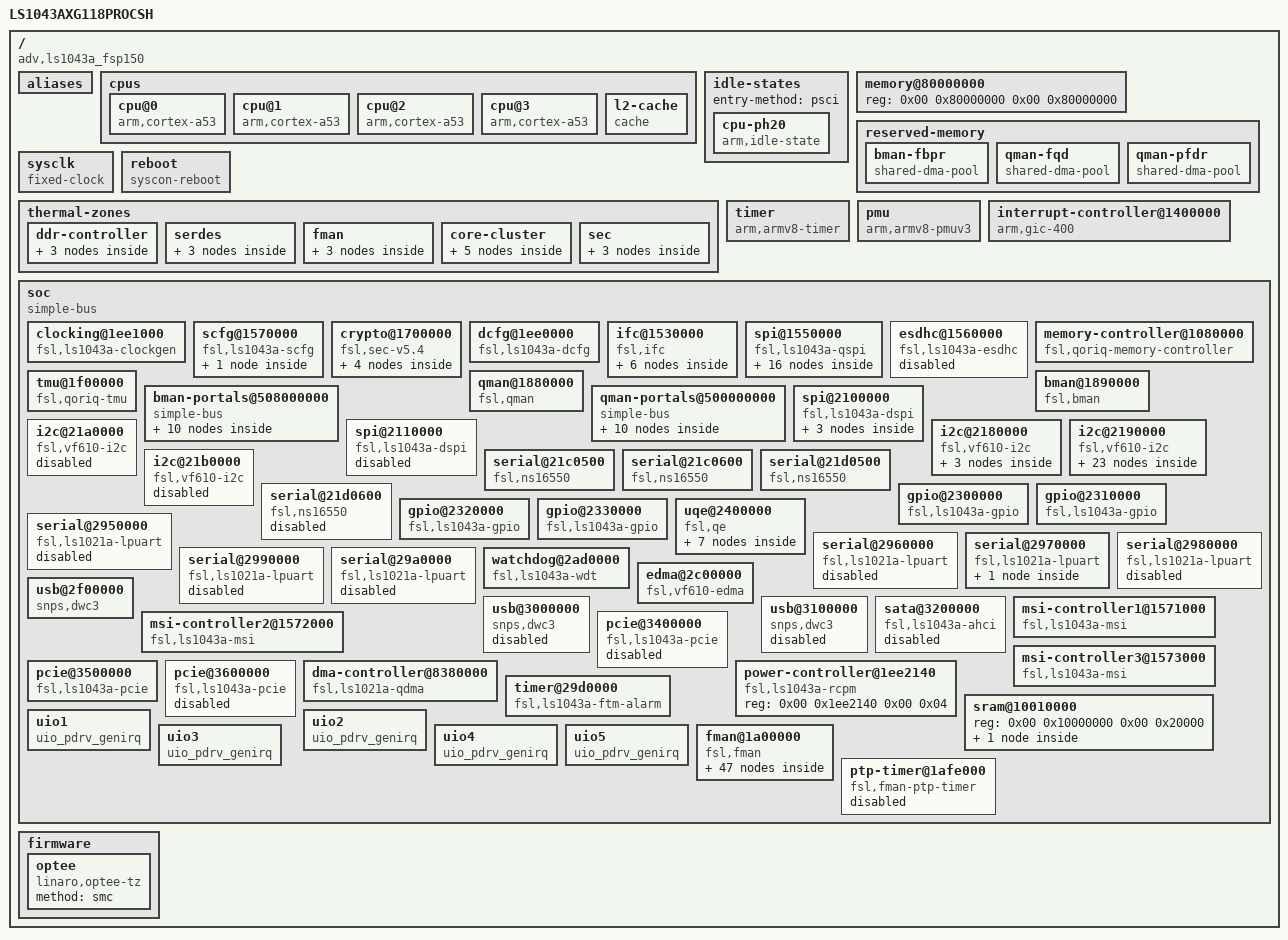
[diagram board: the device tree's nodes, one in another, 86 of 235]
/dts-v1/;

/ {
	revision = "#REV#";
	model = "LS1043AXG118PROCSH";
	compatible = "adv,ls1043a_fsp150\0fsl,ls1043a";
	interrupt-parent = <0x01>;
	#address-cells = <0x02>;
	#size-cells = <0x02>;
	fpga_bus = "pcie";

	aliases {
		crypto = "/soc/crypto@1700000";
		fman0 = "/soc/fman@1a00000";
		ethernet0 = "/soc/fman@1a00000/ethernet@e2000";
		ethernet1 = "/soc/fman@1a00000/ethernet@e4000";
		ethernet2 = "/soc/fman@1a00000/ethernet@f0000";
		rtc1 = "/soc/timer@29d0000";
		serial0 = "/soc/serial@21c0500";
		serial1 = "/soc/serial@21c0600";
		serial2 = "/soc/serial@21d0500";
		lpserial0 = "/soc/serial@2970000";
	};

	cpus {
		#address-cells = <0x01>;
		#size-cells = <0x00>;

		cpu@0 {
			device_type = "cpu";
			compatible = "arm,cortex-a53";
			reg = <0x00>;
			clocks = <0x02 0x01 0x00>;
			next-level-cache = <0x03>;
			cpu-idle-states = <0x04>;
			#cooling-cells = <0x02>;
			phandle = <0x08>;
		};

		cpu@1 {
			device_type = "cpu";
			compatible = "arm,cortex-a53";
			reg = <0x01>;
			clocks = <0x02 0x01 0x00>;
			next-level-cache = <0x03>;
			cpu-idle-states = <0x04>;
			#cooling-cells = <0x02>;
			phandle = <0x09>;
		};

		cpu@2 {
			device_type = "cpu";
			compatible = "arm,cortex-a53";
			reg = <0x02>;
			clocks = <0x02 0x01 0x00>;
			next-level-cache = <0x03>;
			cpu-idle-states = <0x04>;
			#cooling-cells = <0x02>;
			phandle = <0x0a>;
		};

		cpu@3 {
			device_type = "cpu";
			compatible = "arm,cortex-a53";
			reg = <0x03>;
			clocks = <0x02 0x01 0x00>;
			next-level-cache = <0x03>;
			cpu-idle-states = <0x04>;
			#cooling-cells = <0x02>;
			phandle = <0x0b>;
		};

		l2-cache {
			compatible = "cache";
			phandle = <0x03>;
		};
	};

	idle-states {
		entry-method = "psci";

		cpu-ph20 {
			compatible = "arm,idle-state";
			idle-state-name = "PH20";
			arm,psci-suspend-param = <0x00>;
			entry-latency-us = <0x3e8>;
			exit-latency-us = <0x3e8>;
			min-residency-us = <0xbb8>;
			phandle = <0x04>;
		};
	};

	memory@80000000 {
		device_type = "memory";
		reg = <0x00 0x80000000 0x00 0x80000000>;
	};

	reserved-memory {
		#address-cells = <0x02>;
		#size-cells = <0x02>;
		ranges;

		bman-fbpr {
			compatible = "shared-dma-pool";
			size = <0x00 0x1000000>;
			alignment = <0x00 0x1000000>;
			no-map;
			phandle = <0x0f>;
		};

		qman-fqd {
			compatible = "shared-dma-pool";
			size = <0x00 0x400000>;
			alignment = <0x00 0x400000>;
			no-map;
			phandle = <0x0d>;
		};

		qman-pfdr {
			compatible = "shared-dma-pool";
			size = <0x00 0x2000000>;
			alignment = <0x00 0x2000000>;
			no-map;
			phandle = <0x0e>;
		};
	};

	sysclk {
		compatible = "fixed-clock";
		#clock-cells = <0x00>;
		clock-frequency = <0x5f5e100>;
		clock-output-names = "sysclk";
		phandle = <0x0c>;
	};

	reboot {
		compatible = "syscon-reboot";
		regmap = <0x05>;
		offset = <0xb0>;
		mask = <0x02>;
	};

	thermal-zones {

		ddr-controller {
			polling-delay-passive = <0x3e8>;
			polling-delay = <0x1388>;
			thermal-sensors = <0x06 0x00>;

			trips {

				ddr-ctrler-alert {
					temperature = <0x14c08>;
					hysteresis = <0x7d0>;
					type = "passive";
				};

				ddr-ctrler-crit {
					temperature = <0x17318>;
					hysteresis = <0x7d0>;
					type = "critical";
				};
			};
		};

		serdes {
			polling-delay-passive = <0x3e8>;
			polling-delay = <0x1388>;
			thermal-sensors = <0x06 0x01>;

			trips {

				serdes-alert {
					temperature = <0x14c08>;
					hysteresis = <0x7d0>;
					type = "passive";
				};

				serdes-crit {
					temperature = <0x17318>;
					hysteresis = <0x7d0>;
					type = "critical";
				};
			};
		};

		fman {
			polling-delay-passive = <0x3e8>;
			polling-delay = <0x1388>;
			thermal-sensors = <0x06 0x02>;

			trips {

				fman-alert {
					temperature = <0x14c08>;
					hysteresis = <0x7d0>;
					type = "passive";
				};

				fman-crit {
					temperature = <0x17318>;
					hysteresis = <0x7d0>;
					type = "critical";
				};
			};
		};

		core-cluster {
			polling-delay-passive = <0x3e8>;
			polling-delay = <0x1388>;
			thermal-sensors = <0x06 0x03>;

			trips {

				core-cluster-alert {
					temperature = <0x14c08>;
					hysteresis = <0x7d0>;
					type = "passive";
					phandle = <0x07>;
				};

				core-cluster-crit {
					temperature = <0x17318>;
					hysteresis = <0x7d0>;
					type = "critical";
				};
			};

			cooling-maps {

				map0 {
					trip = <0x07>;
					cooling-device = <0x08 0xffffffff 0xffffffff 0x09 0xffffffff 0xffffffff 0x0a 0xffffffff 0xffffffff 0x0b 0xffffffff 0xffffffff>;
				};
			};
		};

		sec {
			polling-delay-passive = <0x3e8>;
			polling-delay = <0x1388>;
			thermal-sensors = <0x06 0x04>;

			trips {

				sec-alert {
					temperature = <0x14c08>;
					hysteresis = <0x7d0>;
					type = "passive";
				};

				sec-crit {
					temperature = <0x17318>;
					hysteresis = <0x7d0>;
					type = "critical";
				};
			};
		};
	};

	timer {
		compatible = "arm,armv8-timer";
		interrupts = <0x01 0x0d 0xf08 0x01 0x0e 0xf08 0x01 0x0b 0xf08 0x01 0x0a 0xf08>;
		fsl,erratum-a008585;
	};

	pmu {
		compatible = "arm,armv8-pmuv3";
		interrupts = <0x00 0x6a 0x04 0x00 0x6b 0x04 0x00 0x5f 0x04 0x00 0x61 0x04>;
		interrupt-affinity = <0x08 0x09 0x0a 0x0b>;
	};

	interrupt-controller@1400000 {
		compatible = "arm,gic-400";
		#interrupt-cells = <0x03>;
		interrupt-controller;
		reg = <0x00 0x1401000 0x00 0x1000 0x00 0x1402000 0x00 0x2000 0x00 0x1404000 0x00 0x2000 0x00 0x1406000 0x00 0x2000>;
		interrupts = <0x01 0x09 0xf08>;
		phandle = <0x01>;
	};

	soc {
		compatible = "simple-bus";
		#address-cells = <0x02>;
		#size-cells = <0x02>;
		ranges;

		clocking@1ee1000 {
			compatible = "fsl,ls1043a-clockgen";
			reg = <0x00 0x1ee1000 0x00 0x1000>;
			#clock-cells = <0x02>;
			clocks = <0x0c>;
			phandle = <0x02>;
		};

		scfg@1570000 {
			compatible = "fsl,ls1043a-scfg\0syscon";
			reg = <0x00 0x1570000 0x00 0x10000>;
			big-endian;
			#address-cells = <0x01>;
			#size-cells = <0x01>;
			ranges = <0x00 0x00 0x1570000 0x10000>;

			interrupt-controller@1ac {
				compatible = "fsl,ls1043a-extirq";
				#interrupt-cells = <0x02>;
				#address-cells = <0x00>;
				interrupt-controller;
				reg = <0x1ac 0x04>;
				interrupt-map = <0x00 0x00 0x01 0x00 0x83 0x04 0x01 0x00 0x01 0x00 0x84 0x04 0x02 0x00 0x01 0x00 0x85 0x04 0x03 0x00 0x01 0x00 0x87 0x04 0x04 0x00 0x01 0x00 0x88 0x04 0x05 0x00 0x01 0x00 0x89 0x04 0x06 0x00 0x01 0x00 0x91 0x04 0x07 0x00 0x01 0x00 0x92 0x04 0x08 0x00 0x01 0x00 0x93 0x04 0x09 0x00 0x01 0x00 0x95 0x04 0x0a 0x00 0x01 0x00 0x96 0x04 0x0b 0x00 0x01 0x00 0x97 0x04>;
				interrupt-map-mask = <0xffffffff 0x00>;
			};
		};

		crypto@1700000 {
			compatible = "fsl,sec-v5.4\0fsl,sec-v5.0\0fsl,sec-v4.0";
			fsl,sec-era = <0x03>;
			#address-cells = <0x01>;
			#size-cells = <0x01>;
			ranges = <0x00 0x00 0x1700000 0x100000>;
			reg = <0x00 0x1700000 0x00 0x100000>;
			interrupts = <0x00 0x4b 0x04>;
			dma-coherent;

			jr@10000 {
				compatible = "fsl,sec-v5.4-job-ring\0fsl,sec-v5.0-job-ring\0fsl,sec-v4.0-job-ring";
				reg = <0x10000 0x10000>;
				interrupts = <0x00 0x47 0x04>;
			};

			jr@20000 {
				compatible = "fsl,sec-v5.4-job-ring\0fsl,sec-v5.0-job-ring\0fsl,sec-v4.0-job-ring";
				reg = <0x20000 0x10000>;
				interrupts = <0x00 0x48 0x04>;
			};

			jr@30000 {
				compatible = "fsl,sec-v5.4-job-ring\0fsl,sec-v5.0-job-ring\0fsl,sec-v4.0-job-ring";
				reg = <0x30000 0x10000>;
				interrupts = <0x00 0x49 0x04>;
			};

			jr@40000 {
				compatible = "fsl,sec-v5.4-job-ring\0fsl,sec-v5.0-job-ring\0fsl,sec-v4.0-job-ring";
				reg = <0x40000 0x10000>;
				interrupts = <0x00 0x4a 0x04>;
			};
		};

		dcfg@1ee0000 {
			compatible = "fsl,ls1043a-dcfg\0syscon";
			reg = <0x00 0x1ee0000 0x00 0x10000>;
			big-endian;
			phandle = <0x05>;
		};

		ifc@1530000 {
			compatible = "fsl,ifc\0simple-bus";
			reg = <0x00 0x1530000 0x00 0x10000>;
			interrupts = <0x00 0x2b 0x04>;
			#address-cells = <0x02>;
			#size-cells = <0x01>;
			status = "okay";
			ranges = <0x00 0x00 0x00 0x68000000 0x10000 0x02 0x00 0x00 0x78000000 0x1000>;

			nand@0,0 {
				compatible = "fsl,ifc-nand";
				#address-cells = <0x02>;
				#size-cells = <0x02>;
				reg = <0x00 0x00 0x10000>;
				num-cs = <0x02>;

				partition@0 {
					label = "ubi";
					reg = <0x00 0x00 0x02 0x00>;
				};
			};

			cpld@2,0 {
				compatible = "fsl,ls1043ardb-cpld\0adv,fsp150-cpld\0uio_pdrv_genirq";
				#address-cells = <0x01>;
				#size-cells = <0x01>;
				reg = <0x02 0x00 0x1000>;
				device-width = <0x02>;
				ranges = <0x00 0x02 0x00 0x200>;
				interrupt-parent = <0x01>;

				hwversion@2 {
					reg = <0x02 0x02>;
				};

				restartcause@fe {
					reg = <0xfe 0x02>;
				};

				watchdog@f6 {
					reg = <0xf6 0x08>;
				};
			};
		};

		spi@1550000 {
			compatible = "fsl,ls1043a-qspi\0fsl,ls1021a-qspi";
			#address-cells = <0x01>;
			#size-cells = <0x00>;
			reg = <0x00 0x1550000 0x00 0x10000 0x00 0x40000000 0x00 0x4000000>;
			reg-names = "QuadSPI\0QuadSPI-memory";
			interrupts = <0x00 0x63 0x04>;
			clock-names = "qspi_en\0qspi";
			clocks = <0x02 0x04 0x00 0x02 0x04 0x00>;
			status = "okay";
			spi-max-frequency = <0x2faf080>;
			fsl,qspi-has-second-chip;

			mx25r1635f@0 {
				compatible = "micronix,mx25r1635f\0jedec,spi-nor";
				#address-cells = <0x01>;
				#size-cells = <0x01>;
				spi-max-frequency = <0x2faf080>;
				reg = <0x00>;

				partition@0 {
					reg = <0x00 0x10000>;
					label = "rcw";
				};

				partition@10000 {
					reg = <0x10000 0xde000>;
					label = "csf";
				};

				partition@ee000 {
					reg = <0xee000 0x1000>;
					label = "env1";
				};

				partition@ef000 {
					reg = <0xef000 0x1000>;
					label = "env2";
				};

				partition@f0000 {
					reg = <0xf0000 0x10000>;
					label = "pbuf";
				};

				partition@100000 {
					reg = <0x100000 0x100000>;
					label = "unused";
				};

				nor@200000 {
					reg = <0x00 0x200000>;
					label = "nor";
				};
			};

			mx25r1635f@1 {
				compatible = "micronix,mx25r1635f\0jedec,spi-nor";
				#address-cells = <0x01>;
				#size-cells = <0x01>;
				spi-max-frequency = <0x2faf080>;
				reg = <0x01>;

				partition@0 {
					reg = <0x00 0x10000>;
					label = "rcw_standby";
				};

				partition@10000 {
					reg = <0x10000 0xde000>;
					label = "csf_standby";
				};

				partition@ee000 {
					reg = <0xee000 0x1000>;
					label = "env1_standby";
				};

				partition@ef000 {
					reg = <0xef000 0x1000>;
					label = "env2_standby";
				};

				partition@f0000 {
					reg = <0xf0000 0x10000>;
					label = "pbuf_standby";
				};

				partition@100000 {
					reg = <0x100000 0x100000>;
					label = "unused_standby";
				};

				nor@200000 {
					reg = <0x00 0x200000>;
					label = "nor_standby";
				};
			};
		};

		esdhc@1560000 {
			compatible = "fsl,ls1043a-esdhc\0fsl,esdhc";
			reg = <0x00 0x1560000 0x00 0x10000>;
			interrupts = <0x00 0x3e 0x04>;
			clock-frequency = <0x00>;
			voltage-ranges = <0x708 0x708 0xce4 0xce4>;
			sdhci,auto-cmd12;
			big-endian;
			bus-width = <0x04>;
			status = "disabled";
		};

		memory-controller@1080000 {
			compatible = "fsl,qoriq-memory-controller";
			reg = <0x00 0x1080000 0x00 0x1000>;
			interrupts = <0x00 0x90 0x04>;
			big-endian;
		};

		tmu@1f00000 {
			compatible = "fsl,qoriq-tmu";
			reg = <0x00 0x1f00000 0x00 0x10000>;
			interrupts = <0x00 0x21 0x04>;
			fsl,tmu-range = <0xb0000 0x9002a 0x6004c 0x70062>;
			fsl,tmu-calibration = <0x00 0x23 0x01 0x2a 0x02 0x31 0x03 0x37 0x04 0x3e 0x05 0x44 0x06 0x4b 0x07 0x51 0x08 0x58 0x09 0x5e 0x0a 0x65 0x0b 0x6b 0x10000 0x23 0x10001 0x2b 0x10002 0x33 0x10003 0x3b 0x10004 0x43 0x10005 0x4b 0x10006 0x54 0x10007 0x5c 0x10008 0x64 0x10009 0x6c 0x20000 0x21 0x20001 0x2c 0x20002 0x36 0x20003 0x40 0x20004 0x4b 0x20005 0x55 0x20006 0x5f 0x30000 0x13 0x30001 0x1d 0x30002 0x28 0x30003 0x32 0x30004 0x3d 0x30005 0x47 0x30006 0x52 0x30007 0x5c>;
			#thermal-sensor-cells = <0x01>;
			phandle = <0x06>;
		};

		qman@1880000 {
			compatible = "fsl,qman";
			reg = <0x00 0x1880000 0x00 0x10000>;
			interrupts = <0x00 0x2d 0x04>;
			memory-region = <0x0d 0x0e>;
		};

		bman@1890000 {
			compatible = "fsl,bman";
			reg = <0x00 0x1890000 0x00 0x10000>;
			interrupts = <0x00 0x2d 0x04>;
			memory-region = <0x0f>;
		};

		bman-portals@508000000 {
			ranges = <0x00 0x05 0x8000000 0x8000000>;
			#address-cells = <0x01>;
			#size-cells = <0x01>;
			compatible = "simple-bus";

			bman-portal@0 {
				compatible = "fsl,bman-portal";
				reg = <0x00 0x4000 0x4000000 0x4000>;
				interrupts = <0x00 0xad 0x04>;
			};

			bman-portal@10000 {
				compatible = "fsl,bman-portal";
				reg = <0x10000 0x4000 0x4010000 0x4000>;
				interrupts = <0x00 0xaf 0x04>;
			};

			bman-portal@20000 {
				compatible = "fsl,bman-portal";
				reg = <0x20000 0x4000 0x4020000 0x4000>;
				interrupts = <0x00 0xb1 0x04>;
			};

			bman-portal@30000 {
				compatible = "fsl,bman-portal";
				reg = <0x30000 0x4000 0x4030000 0x4000>;
				interrupts = <0x00 0xb3 0x04>;
			};

			bman-portal@40000 {
				compatible = "fsl,bman-portal";
				reg = <0x40000 0x4000 0x4040000 0x4000>;
				interrupts = <0x00 0xb5 0x04>;
			};

			bman-portal@50000 {
				compatible = "fsl,bman-portal";
				reg = <0x50000 0x4000 0x4050000 0x4000>;
				interrupts = <0x00 0xb7 0x04>;
			};

			bman-portal@60000 {
				compatible = "fsl,bman-portal";
				reg = <0x60000 0x4000 0x4060000 0x4000>;
				interrupts = <0x00 0xb9 0x04>;
			};

			bman-portal@70000 {
				compatible = "fsl,bman-portal";
				reg = <0x70000 0x4000 0x4070000 0x4000>;
				interrupts = <0x00 0xbb 0x04>;
			};

			bman-portal@80000 {
				compatible = "fsl,bman-portal";
				reg = <0x80000 0x4000 0x4080000 0x4000>;
				interrupts = <0x00 0xbd 0x04>;
			};

			bman-portal@90000 {
				compatible = "fsl,bman-portal";
				reg = <0x90000 0x4000 0x4090000 0x4000>;
				interrupts = <0x00 0xbf 0x04>;
			};
		};

		qman-portals@500000000 {
			ranges = <0x00 0x05 0x00 0x8000000>;
			#address-cells = <0x01>;
			#size-cells = <0x01>;
			compatible = "simple-bus";

			qman-portal@0 {
				compatible = "fsl,qman-portal";
				reg = <0x00 0x4000 0x4000000 0x4000>;
				interrupts = <0x00 0xac 0x04>;
				cell-index = <0x00>;
			};

			qman-portal@10000 {
				compatible = "fsl,qman-portal";
				reg = <0x10000 0x4000 0x4010000 0x4000>;
				interrupts = <0x00 0xae 0x04>;
				cell-index = <0x01>;
			};

			qman-portal@20000 {
				compatible = "fsl,qman-portal";
				reg = <0x20000 0x4000 0x4020000 0x4000>;
				interrupts = <0x00 0xb0 0x04>;
				cell-index = <0x02>;
			};

			qman-portal@30000 {
				compatible = "fsl,qman-portal";
				reg = <0x30000 0x4000 0x4030000 0x4000>;
				interrupts = <0x00 0xb2 0x04>;
				cell-index = <0x03>;
			};

			qman-portal@40000 {
				compatible = "fsl,qman-portal";
				reg = <0x40000 0x4000 0x4040000 0x4000>;
				interrupts = <0x00 0xb4 0x04>;
				cell-index = <0x04>;
			};

			qman-portal@50000 {
				compatible = "fsl,qman-portal";
				reg = <0x50000 0x4000 0x4050000 0x4000>;
				interrupts = <0x00 0xb6 0x04>;
				cell-index = <0x05>;
			};

			qman-portal@60000 {
				compatible = "fsl,qman-portal";
				reg = <0x60000 0x4000 0x4060000 0x4000>;
				interrupts = <0x00 0xb8 0x04>;
				cell-index = <0x06>;
			};

			qman-portal@70000 {
				compatible = "fsl,qman-portal";
				reg = <0x70000 0x4000 0x4070000 0x4000>;
				interrupts = <0x00 0xba 0x04>;
				cell-index = <0x07>;
			};

			qman-portal@80000 {
				compatible = "fsl,qman-portal";
				reg = <0x80000 0x4000 0x4080000 0x4000>;
				interrupts = <0x00 0xbc 0x04>;
				cell-index = <0x08>;
			};

			qman-portal@90000 {
				compatible = "fsl,qman-portal";
				reg = <0x90000 0x4000 0x4090000 0x4000>;
				interrupts = <0x00 0xbe 0x04>;
				cell-index = <0x09>;
			};
		};

		spi@2100000 {
			compatible = "fsl,ls1043a-dspi\0fsl,ls1021a-v1.0-dspi";
			#address-cells = <0x01>;
			#size-cells = <0x00>;
			reg = <0x00 0x2100000 0x00 0x10000>;
			interrupts = <0x00 0x40 0x04>;
			clock-names = "dspi";
			clocks = <0x02 0x04 0x00>;
			spi-num-chipselects = <0x03>;
			big-endian;
			status = "okay";
			bus-num = <0x00>;

			cs0@0 {
				compatible = "adv,spidev";
				spi-max-frequency = <0xf4240>;
				fsl,spi-cs-sck-delay = <0x32>;
				fsl,spi-sck-cs-delay = <0x32>;
				mode = <0x00>;
				reg = <0x00>;
			};

			cs1@1 {
				compatible = "adv,spidev";
				spi-max-frequency = <0xf4240>;
				fsl,spi-cs-sck-delay = <0x32>;
				fsl,spi-sck-cs-delay = <0x32>;
				mode = <0x00>;
				reg = <0x01>;
			};

			cs2@2 {
				compatible = "adv,spidev";
				spi-max-frequency = <0xf4240>;
				fsl,spi-cs-sck-delay = <0x69>;
				fsl,spi-sck-cs-delay = <0x6e>;
				mode = <0x00>;
				reg = <0x02>;
			};
		};

		spi@2110000 {
			compatible = "fsl,ls1043a-dspi\0fsl,ls1021a-v1.0-dspi";
			#address-cells = <0x01>;
			#size-cells = <0x00>;
			reg = <0x00 0x2110000 0x00 0x10000>;
			interrupts = <0x00 0x41 0x04>;
			clock-names = "dspi";
			clocks = <0x02 0x04 0x00>;
			spi-num-chipselects = <0x05>;
			big-endian;
			status = "disabled";
		};

		i2c@2180000 {
			compatible = "fsl,vf610-i2c";
			#address-cells = <0x01>;
			#size-cells = <0x00>;
			reg = <0x00 0x2180000 0x00 0x10000>;
			interrupts = <0x00 0x38 0x04>;
			clock-names = "i2c";
			clocks = <0x02 0x04 0x00>;
			dmas = <0x10 0x01 0x26 0x10 0x01 0x27>;
			dma-names = "rx\0tx";
			status = "okay";
			gpios = <0x11 0x1c 0x02 0x11 0x1f 0x02>;

			mcp9808@18 {
				compatible = "maxim,mcp980x";
				reg = <0x18>;
			};

			at24c08@54 {
				compatible = "atmel,24c08";
				reg = <0x54>;
			};

			rtc@68 {
				compatible = "dallas,ds1340";
				reg = <0x68>;
			};
		};

		i2c@2190000 {
			compatible = "fsl,vf610-i2c";
			#address-cells = <0x01>;
			#size-cells = <0x00>;
			reg = <0x00 0x2190000 0x00 0x10000>;
			interrupts = <0x00 0x39 0x04>;
			clock-names = "i2c";
			clocks = <0x02 0x04 0x00>;
			status = "okay";
			gpios = <0x11 0x1b 0x02 0x11 0x1a 0x02>;

			mux1@71 {
				compatible = "nxp,pca9548";
				reg = <0x71>;
				#address-cells = <0x01>;
				#size-cells = <0x00>;
				i2c-mux-idle-disconnect;

				channel0@0 {
					#address-cells = <0x01>;
					#size-cells = <0x00>;
					reg = <0x00>;
				};

				channel1@1 {
					#address-cells = <0x01>;
					#size-cells = <0x00>;
					reg = <0x01>;
				};

				channel2@2 {
					#address-cells = <0x01>;
					#size-cells = <0x00>;
					reg = <0x02>;
				};

				channel3@3 {
					#address-cells = <0x01>;
					#size-cells = <0x00>;
					reg = <0x03>;
				};

				channel4@4 {
					#address-cells = <0x01>;
					#size-cells = <0x00>;
					reg = <0x04>;
				};

				channel5@5 {
					#address-cells = <0x01>;
					#size-cells = <0x00>;
					reg = <0x05>;
				};

				channel6@6 {
					#address-cells = <0x01>;
					#size-cells = <0x00>;
					reg = <0x06>;
				};

				channel7@7 {
					#address-cells = <0x01>;
					#size-cells = <0x00>;
					reg = <0x07>;
				};
			};

			mux2@72 {
				compatible = "nxp,pca9548";
				reg = <0x72>;
				#address-cells = <0x01>;
				#size-cells = <0x00>;
				i2c-mux-idle-disconnect;

				channel0@0 {
					#address-cells = <0x01>;
					#size-cells = <0x00>;
					reg = <0x00>;
				};

				channel1@1 {
					#address-cells = <0x01>;
					#size-cells = <0x00>;
					reg = <0x01>;
				};

				channel2@2 {
					#address-cells = <0x01>;
					#size-cells = <0x00>;
					reg = <0x02>;
				};

				channel3@3 {
					#address-cells = <0x01>;
					#size-cells = <0x00>;
					reg = <0x03>;
				};

				channel4@4 {
					#address-cells = <0x01>;
					#size-cells = <0x00>;
					reg = <0x04>;
				};

				channel5@5 {
					#address-cells = <0x01>;
					#size-cells = <0x00>;
					reg = <0x05>;
				};

				channel6@6 {
					#address-cells = <0x01>;
					#size-cells = <0x00>;
					reg = <0x06>;
				};

				channel7@7 {
					#address-cells = <0x01>;
					#size-cells = <0x00>;
					reg = <0x07>;
				};
			};

			mux3@70 {
				compatible = "nxp,pca9545";
				reg = <0x70>;
				#address-cells = <0x01>;
				#size-cells = <0x00>;
				i2c-mux-idle-disconnect;

				channel0@0 {
					#address-cells = <0x01>;
					#size-cells = <0x00>;
					reg = <0x00>;
				};

				channel1@1 {
					#address-cells = <0x01>;
					#size-cells = <0x00>;
					reg = <0x01>;
				};

				channel2@2 {
					#address-cells = <0x01>;
					#size-cells = <0x00>;
					reg = <0x02>;
				};

				channel3@3 {
					#address-cells = <0x01>;
					#size-cells = <0x00>;
					reg = <0x03>;
				};
			};
		};

		i2c@21a0000 {
			compatible = "fsl,vf610-i2c";
			#address-cells = <0x01>;
			#size-cells = <0x00>;
			reg = <0x00 0x21a0000 0x00 0x10000>;
			interrupts = <0x00 0x3a 0x04>;
			clock-names = "i2c";
			clocks = <0x02 0x04 0x00>;
			status = "disabled";
		};

		i2c@21b0000 {
			compatible = "fsl,vf610-i2c";
			#address-cells = <0x01>;
			#size-cells = <0x00>;
			reg = <0x00 0x21b0000 0x00 0x10000>;
			interrupts = <0x00 0x3b 0x04>;
			clock-names = "i2c";
			clocks = <0x02 0x04 0x00>;
			status = "disabled";
		};

		serial@21c0500 {
			compatible = "fsl,ns16550\0ns16550a";
			reg = <0x00 0x21c0500 0x00 0x100>;
			interrupts = <0x00 0x36 0x04>;
			clocks = <0x02 0x04 0x00>;
			status = "okay";
		};

		serial@21c0600 {
			compatible = "fsl,ns16550\0ns16550a";
			reg = <0x00 0x21c0600 0x00 0x100>;
			interrupts = <0x00 0x36 0x04>;
			clocks = <0x02 0x04 0x00>;
			status = "okay";
		};

		serial@21d0500 {
			compatible = "fsl,ns16550\0ns16550a";
			reg = <0x00 0x21d0500 0x00 0x100>;
			interrupts = <0x00 0x37 0x04>;
			clocks = <0x02 0x04 0x00>;
			status = "okay";
		};

		serial@21d0600 {
			compatible = "fsl,ns16550\0ns16550a";
			reg = <0x00 0x21d0600 0x00 0x100>;
			interrupts = <0x00 0x37 0x04>;
			clocks = <0x02 0x04 0x00>;
			status = "disabled";
		};

		gpio@2300000 {
			compatible = "fsl,ls1043a-gpio\0fsl,qoriq-gpio";
			reg = <0x00 0x2300000 0x00 0x10000>;
			interrupts = <0x00 0x42 0x04>;
			gpio-controller;
			#gpio-cells = <0x02>;
			interrupt-controller;
			#interrupt-cells = <0x02>;
			phandle = <0x11>;
		};

		gpio@2310000 {
			compatible = "fsl,ls1043a-gpio\0fsl,qoriq-gpio";
			reg = <0x00 0x2310000 0x00 0x10000>;
			interrupts = <0x00 0x43 0x04>;
			gpio-controller;
			#gpio-cells = <0x02>;
			interrupt-controller;
			#interrupt-cells = <0x02>;
		};

		gpio@2320000 {
			compatible = "fsl,ls1043a-gpio\0fsl,qoriq-gpio";
			reg = <0x00 0x2320000 0x00 0x10000>;
			interrupts = <0x00 0x44 0x04>;
			gpio-controller;
			#gpio-cells = <0x02>;
			interrupt-controller;
			#interrupt-cells = <0x02>;
		};

		gpio@2330000 {
			compatible = "fsl,ls1043a-gpio\0fsl,qoriq-gpio";
			reg = <0x00 0x2330000 0x00 0x10000>;
			interrupts = <0x00 0x86 0x04>;
			gpio-controller;
			#gpio-cells = <0x02>;
			interrupt-controller;
			#interrupt-cells = <0x02>;
		};

		uqe@2400000 {
			#address-cells = <0x01>;
			#size-cells = <0x01>;
			compatible = "fsl,qe\0simple-bus";
			ranges = <0x00 0x00 0x2400000 0x40000>;
			reg = <0x00 0x2400000 0x00 0x480>;
			brg-frequency = <0x5f5e100>;
			bus-frequency = <0xbebc200>;
			fsl,qe-num-riscs = <0x01>;
			fsl,qe-num-snums = <0x1c>;

			qeic@80 {
				compatible = "fsl,qe-ic";
				reg = <0x80 0x80>;
				#address-cells = <0x00>;
				interrupt-controller;
				#interrupt-cells = <0x01>;
				interrupts = <0x00 0x4d 0x04 0x00 0x4d 0x04>;
				phandle = <0x12>;
			};

			si@700 {
				#address-cells = <0x01>;
				#size-cells = <0x00>;
				compatible = "fsl,ls1043-qe-si\0fsl,t1040-qe-si";
				reg = <0x700 0x80>;
			};

			siram@1000 {
				#address-cells = <0x01>;
				#size-cells = <0x01>;
				compatible = "fsl,ls1043-qe-siram\0fsl,t1040-qe-siram";
				reg = <0x1000 0x800>;
			};

			ucc@2000 {
				cell-index = <0x01>;
				reg = <0x2000 0x200>;
				interrupts = <0x20>;
				interrupt-parent = <0x12>;
			};

			ucc@2200 {
				cell-index = <0x03>;
				reg = <0x2200 0x200>;
				interrupts = <0x22>;
				interrupt-parent = <0x12>;
			};

			muram@10000 {
				#address-cells = <0x01>;
				#size-cells = <0x01>;
				compatible = "fsl,qe-muram\0fsl,cpm-muram";
				ranges = <0x00 0x10000 0x6000>;

				data-only@0 {
					compatible = "fsl,qe-muram-data\0fsl,cpm-muram-data";
					reg = <0x00 0x6000>;
				};
			};
		};

		serial@2950000 {
			compatible = "fsl,ls1021a-lpuart";
			reg = <0x00 0x2950000 0x00 0x1000>;
			interrupts = <0x00 0x30 0x04>;
			clocks = <0x02 0x00 0x00>;
			clock-names = "ipg";
			status = "disabled";
		};

		serial@2960000 {
			compatible = "fsl,ls1021a-lpuart";
			reg = <0x00 0x2960000 0x00 0x1000>;
			interrupts = <0x00 0x31 0x04>;
			clocks = <0x02 0x04 0x00>;
			clock-names = "ipg";
			status = "disabled";
		};

		serial@2970000 {
			compatible = "fsl,ls1021a-lpuart";
			reg = <0x00 0x2970000 0x00 0x1000>;
			interrupts = <0x00 0x32 0x04>;
			clocks = <0x02 0x04 0x00>;
			clock-names = "ipg";
			status = "okay";

			serial_dtr_dsr {
				gpios = <0x11 0x1d 0x00 0x11 0x1e 0x00>;
			};
		};

		serial@2980000 {
			compatible = "fsl,ls1021a-lpuart";
			reg = <0x00 0x2980000 0x00 0x1000>;
			interrupts = <0x00 0x33 0x04>;
			clocks = <0x02 0x04 0x00>;
			clock-names = "ipg";
			status = "disabled";
		};

		serial@2990000 {
			compatible = "fsl,ls1021a-lpuart";
			reg = <0x00 0x2990000 0x00 0x1000>;
			interrupts = <0x00 0x34 0x04>;
			clocks = <0x02 0x04 0x00>;
			clock-names = "ipg";
			status = "disabled";
		};

		serial@29a0000 {
			compatible = "fsl,ls1021a-lpuart";
			reg = <0x00 0x29a0000 0x00 0x1000>;
			interrupts = <0x00 0x35 0x04>;
			clocks = <0x02 0x04 0x00>;
			clock-names = "ipg";
			status = "disabled";
		};

		watchdog@2ad0000 {
			compatible = "fsl,ls1043a-wdt\0fsl,imx21-wdt";
			reg = <0x00 0x2ad0000 0x00 0x10000>;
			interrupts = <0x00 0x53 0x04>;
			clocks = <0x02 0x04 0x00>;
			clock-names = "wdog";
			big-endian;
		};

		edma@2c00000 {
			#dma-cells = <0x02>;
			compatible = "fsl,vf610-edma";
			reg = <0x00 0x2c00000 0x00 0x10000 0x00 0x2c10000 0x00 0x10000 0x00 0x2c20000 0x00 0x10000>;
			interrupts = <0x00 0x67 0x04 0x00 0x67 0x04>;
			interrupt-names = "edma-tx\0edma-err";
			dma-channels = <0x20>;
			big-endian;
			clock-names = "dmamux0\0dmamux1";
			clocks = <0x02 0x04 0x00 0x02 0x04 0x00>;
			phandle = <0x10>;
		};

		usb@2f00000 {
			compatible = "snps,dwc3";
			reg = <0x00 0x2f00000 0x00 0x10000>;
			interrupts = <0x00 0x3c 0x04>;
			dr_mode = "host";
			snps,quirk-frame-length-adjustment = <0x20>;
			snps,dis_rxdet_inp3_quirk;
			snps,incr-burst-type-adjustment = <0x01 0x04 0x08 0x10>;
			status = "okay";
		};

		usb@3000000 {
			compatible = "snps,dwc3";
			reg = <0x00 0x3000000 0x00 0x10000>;
			interrupts = <0x00 0x3d 0x04>;
			dr_mode = "host";
			snps,quirk-frame-length-adjustment = <0x20>;
			snps,dis_rxdet_inp3_quirk;
			snps,incr-burst-type-adjustment = <0x01 0x04 0x08 0x10>;
			status = "disabled";
		};

		usb@3100000 {
			compatible = "snps,dwc3";
			reg = <0x00 0x3100000 0x00 0x10000>;
			interrupts = <0x00 0x3f 0x04>;
			dr_mode = "host";
			snps,quirk-frame-length-adjustment = <0x20>;
			snps,dis_rxdet_inp3_quirk;
			snps,incr-burst-type-adjustment = <0x01 0x04 0x08 0x10>;
			status = "disabled";
		};

		sata@3200000 {
			compatible = "fsl,ls1043a-ahci";
			reg = <0x00 0x3200000 0x00 0x10000 0x00 0x20140520 0x00 0x04>;
			reg-names = "ahci\0sata-ecc";
			interrupts = <0x00 0x45 0x04>;
			clocks = <0x02 0x04 0x00>;
			dma-coherent;
			status = "disabled";
		};

		msi-controller1@1571000 {
			compatible = "fsl,ls1043a-msi";
			reg = <0x00 0x1571000 0x00 0x08>;
			msi-controller;
			interrupts = <0x00 0x74 0x04>;
			phandle = <0x13>;
		};

		msi-controller2@1572000 {
			compatible = "fsl,ls1043a-msi";
			reg = <0x00 0x1572000 0x00 0x08>;
			msi-controller;
			interrupts = <0x00 0x7e 0x04>;
			phandle = <0x14>;
		};

		msi-controller3@1573000 {
			compatible = "fsl,ls1043a-msi";
			reg = <0x00 0x1573000 0x00 0x08>;
			msi-controller;
			interrupts = <0x00 0xa0 0x04>;
			phandle = <0x15>;
		};

		pcie@3400000 {
			compatible = "fsl,ls1043a-pcie";
			reg = <0x00 0x3400000 0x00 0x100000 0x40 0x00 0x00 0x2000>;
			reg-names = "regs\0config";
			interrupts = <0x00 0x76 0x04 0x00 0x75 0x04>;
			interrupt-names = "intr\0pme";
			#address-cells = <0x03>;
			#size-cells = <0x02>;
			device_type = "pci";
			dma-coherent;
			num-viewport = <0x06>;
			bus-range = <0x00 0xff>;
			ranges = <0x81000000 0x00 0x00 0x40 0x10000 0x00 0x10000 0x82000000 0x00 0x40000000 0x40 0x40000000 0x00 0x40000000>;
			msi-parent = <0x13 0x14 0x15>;
			#interrupt-cells = <0x01>;
			interrupt-map-mask = <0x00 0x00 0x00 0x07>;
			interrupt-map = <0x00 0x00 0x00 0x01 0x01 0x00 0x6e 0x04 0x00 0x00 0x00 0x02 0x01 0x00 0x6f 0x04 0x00 0x00 0x00 0x03 0x01 0x00 0x70 0x04 0x00 0x00 0x00 0x04 0x01 0x00 0x71 0x04>;
			status = "disabled";
		};

		pcie@3500000 {
			compatible = "fsl,ls1043a-pcie";
			reg = <0x00 0x3500000 0x00 0x100000 0x48 0x00 0x00 0x2000>;
			reg-names = "regs\0config";
			interrupts = <0x00 0x80 0x04 0x00 0x7f 0x04>;
			interrupt-names = "intr\0pme";
			#address-cells = <0x03>;
			#size-cells = <0x02>;
			device_type = "pci";
			dma-coherent;
			num-viewport = <0x06>;
			bus-range = <0x00 0xff>;
			ranges = <0x81000000 0x00 0x00 0x48 0x10000 0x00 0x10000 0x82000000 0x00 0x40000000 0x48 0x40000000 0x00 0x40000000>;
			msi-parent = <0x13 0x14 0x15>;
			#interrupt-cells = <0x01>;
			interrupt-map-mask = <0x00 0x00 0x00 0x07>;
			interrupt-map = <0x00 0x00 0x00 0x01 0x01 0x00 0x78 0x04 0x00 0x00 0x00 0x02 0x01 0x00 0x79 0x04 0x00 0x00 0x00 0x03 0x01 0x00 0x7a 0x04 0x00 0x00 0x00 0x04 0x01 0x00 0x7b 0x04>;
			status = "okay";
			num-lanes = <0x01>;
		};

		pcie@3600000 {
			compatible = "fsl,ls1043a-pcie";
			reg = <0x00 0x3600000 0x00 0x100000 0x50 0x00 0x00 0x2000>;
			reg-names = "regs\0config";
			interrupts = <0x00 0xa2 0x04 0x00 0xa1 0x04>;
			interrupt-names = "intr\0pme";
			#address-cells = <0x03>;
			#size-cells = <0x02>;
			device_type = "pci";
			dma-coherent;
			num-viewport = <0x06>;
			bus-range = <0x00 0xff>;
			ranges = <0x81000000 0x00 0x00 0x50 0x10000 0x00 0x10000 0x82000000 0x00 0x40000000 0x50 0x40000000 0x00 0x40000000>;
			msi-parent = <0x13 0x14 0x15>;
			#interrupt-cells = <0x01>;
			interrupt-map-mask = <0x00 0x00 0x00 0x07>;
			interrupt-map = <0x00 0x00 0x00 0x01 0x01 0x00 0x9a 0x04 0x00 0x00 0x00 0x02 0x01 0x00 0x9b 0x04 0x00 0x00 0x00 0x03 0x01 0x00 0x9c 0x04 0x00 0x00 0x00 0x04 0x01 0x00 0x9d 0x04>;
			status = "disabled";
		};

		dma-controller@8380000 {
			compatible = "fsl,ls1021a-qdma\0fsl,ls1043a-qdma";
			reg = <0x00 0x8380000 0x00 0x1000 0x00 0x8390000 0x00 0x10000 0x00 0x83a0000 0x00 0x40000>;
			interrupts = <0x00 0x99 0x04 0x00 0x27 0x04 0x00 0x28 0x04 0x00 0x29 0x04 0x00 0x2a 0x04>;
			interrupt-names = "qdma-error\0qdma-queue0\0qdma-queue1\0qdma-queue2\0qdma-queue3";
			dma-channels = <0x08>;
			block-number = <0x01>;
			block-offset = <0x10000>;
			fsl,dma-queues = <0x02>;
			status-sizes = <0x40>;
			queue-sizes = <0x40 0x40>;
			big-endian;
		};

		power-controller@1ee2140 {
			compatible = "fsl,ls1043a-rcpm\0fsl,qoriq-rcpm-2.1+";
			reg = <0x00 0x1ee2140 0x00 0x04>;
			#fsl,rcpm-wakeup-cells = <0x01>;
			phandle = <0x16>;
		};

		timer@29d0000 {
			compatible = "fsl,ls1043a-ftm-alarm";
			reg = <0x00 0x29d0000 0x00 0x10000>;
			fsl,rcpm-wakeup = <0x16 0x20000>;
			interrupts = <0x00 0x56 0x04>;
			big-endian;
		};

		sram@10010000 {
			#address-cells = <0x01>;
			#size-cells = <0x01>;
			reg = <0x00 0x10000000 0x00 0x20000>;
			ranges = <0x00 0x00 0x10000000 0x20000>;

			pbuf@10000 {
				compatible = "adv,sram-pbuf";
				reg = <0x10000 0x10000>;
			};
		};

		uio1 {
			interrupt-parent = <0x01>;
			compatible = "uio_pdrv_genirq";
			interrupts = <0x00 0x83 0x08>;
		};

		uio2 {
			interrupt-parent = <0x01>;
			compatible = "uio_pdrv_genirq";
			interrupts = <0x00 0x84 0x08>;
		};

		uio3 {
			interrupt-parent = <0x01>;
			compatible = "uio_pdrv_genirq";
			interrupts = <0x00 0x85 0x08>;
		};

		uio4 {
			interrupt-parent = <0x01>;
			compatible = "uio_pdrv_genirq";
			interrupts = <0x00 0x87 0x08>;
		};

		uio5 {
			interrupt-parent = <0x01>;
			compatible = "uio_pdrv_genirq";
			interrupts = <0x00 0x88 0x08>;
		};

		fman@1a00000 {
			#address-cells = <0x01>;
			#size-cells = <0x01>;
			cell-index = <0x00>;
			compatible = "fsl,fman";
			ranges = <0x00 0x00 0x1a00000 0xfe000>;
			reg = <0x00 0x1a00000 0x00 0xfe000>;
			interrupts = <0x00 0x2c 0x04 0x00 0x2d 0x04>;
			clocks = <0x02 0x03 0x00>;
			clock-names = "fmanclk";
			fsl,qman-channel-range = <0x800 0x10>;
			ptimer-handle = <0x17>;
			dma-coherent;
			fsl,erratum-a050385;
			fsl,fm_max_frm = <0x2600>;

			muram@0 {
				compatible = "fsl,fman-muram";
				reg = <0x00 0x60000>;
			};

			port@82000 {
				cell-index = <0x02>;
				compatible = "fsl,fman-v3-port-oh";
				reg = <0x82000 0x1000>;
			};

			port@83000 {
				cell-index = <0x03>;
				compatible = "fsl,fman-v3-port-oh";
				reg = <0x83000 0x1000>;
			};

			port@84000 {
				cell-index = <0x04>;
				compatible = "fsl,fman-v3-port-oh";
				reg = <0x84000 0x1000>;
			};

			port@85000 {
				cell-index = <0x05>;
				compatible = "fsl,fman-v3-port-oh";
				reg = <0x85000 0x1000>;
			};

			port@86000 {
				cell-index = <0x06>;
				compatible = "fsl,fman-v3-port-oh";
				reg = <0x86000 0x1000>;
			};

			port@87000 {
				cell-index = <0x07>;
				compatible = "fsl,fman-v3-port-oh";
				reg = <0x87000 0x1000>;
			};

			mdio@fc000 {
				#address-cells = <0x01>;
				#size-cells = <0x00>;
				compatible = "fsl,fman-memac-mdio\0fsl,fman-xmdio\0adv,mdio";
				reg = <0xfc000 0x1000>;
			};

			mdio@fd000 {
				#address-cells = <0x01>;
				#size-cells = <0x00>;
				compatible = "fsl,fman-memac-mdio\0fsl,fman-xmdio";
				reg = <0xfd000 0x1000>;
				status = "disabled";
			};

			port@88000 {
				cell-index = <0x08>;
				compatible = "fsl,fman-v3-port-rx";
				reg = <0x88000 0x1000>;
				phandle = <0x18>;
			};

			port@a8000 {
				cell-index = <0x28>;
				compatible = "fsl,fman-v3-port-tx";
				reg = <0xa8000 0x1000>;
				phandle = <0x19>;
			};

			ethernet@e0000 {
				cell-index = <0x00>;
				compatible = "fsl,fman-memac";
				reg = <0xe0000 0x1000>;
				fsl,fman-ports = <0x18 0x19>;
				ptp-timer = <0x17>;
				pcsphy-handle = <0x1a>;
				status = "disabled";
			};

			mdio@e1000 {
				#address-cells = <0x01>;
				#size-cells = <0x00>;
				compatible = "fsl,fman-memac-mdio\0fsl,fman-xmdio";
				reg = <0xe1000 0x1000>;
				status = "disabled";

				ethernet-phy@0 {
					reg = <0x00>;
					phandle = <0x1a>;
				};
			};

			port@89000 {
				cell-index = <0x09>;
				compatible = "fsl,fman-v3-port-rx";
				reg = <0x89000 0x1000>;
				phandle = <0x1b>;
			};

			port@a9000 {
				cell-index = <0x29>;
				compatible = "fsl,fman-v3-port-tx";
				reg = <0xa9000 0x1000>;
				phandle = <0x1c>;
			};

			ethernet@e2000 {
				cell-index = <0x01>;
				compatible = "fsl,fman-memac";
				reg = <0xe2000 0x1000>;
				fsl,fman-ports = <0x1b 0x1c>;
				ptp-timer = <0x17>;
				pcsphy-handle = <0x1d>;
				phy-connection-type = "sgmii";
				local-mac-address = [00 00 00 00 00 00];

				fixed-link {
					speed = <0x3e8>;
					full-duplex;
				};
			};

			mdio@e3000 {
				#address-cells = <0x01>;
				#size-cells = <0x00>;
				compatible = "fsl,fman-memac-mdio\0fsl,fman-xmdio\0adv,mdio-tbi2";
				reg = <0xe3000 0x1000>;

				ethernet-phy@0 {
					reg = <0x00>;
					sgmii-autoneg;
					phandle = <0x1d>;
				};
			};

			port@8a000 {
				cell-index = <0x0a>;
				compatible = "fsl,fman-v3-port-rx";
				reg = <0x8a000 0x1000>;
				phandle = <0x1e>;
			};

			port@aa000 {
				cell-index = <0x2a>;
				compatible = "fsl,fman-v3-port-tx";
				reg = <0xaa000 0x1000>;
				phandle = <0x1f>;
			};

			ethernet@e4000 {
				cell-index = <0x02>;
				compatible = "fsl,fman-memac";
				reg = <0xe4000 0x1000>;
				fsl,fman-ports = <0x1e 0x1f>;
				ptp-timer = <0x17>;
				pcsphy-handle = <0x20>;
				phy-connection-type = "rgmii-id";
				local-mac-address = [00 00 00 00 00 00];

				fixed-link {
					speed = <0x3e8>;
					full-duplex;
				};
			};

			mdio@e5000 {
				#address-cells = <0x01>;
				#size-cells = <0x00>;
				compatible = "fsl,fman-memac-mdio\0fsl,fman-xmdio";
				reg = <0xe5000 0x1000>;

				ethernet-phy@0 {
					reg = <0x00>;
					phandle = <0x20>;
				};
			};

			port@8b000 {
				cell-index = <0x0b>;
				compatible = "fsl,fman-v3-port-rx";
				reg = <0x8b000 0x1000>;
				phandle = <0x21>;
			};

			port@ab000 {
				cell-index = <0x2b>;
				compatible = "fsl,fman-v3-port-tx";
				reg = <0xab000 0x1000>;
				phandle = <0x22>;
			};

			ethernet@e6000 {
				cell-index = <0x03>;
				compatible = "fsl,fman-memac";
				reg = <0xe6000 0x1000>;
				fsl,fman-ports = <0x21 0x22>;
				ptp-timer = <0x17>;
				pcsphy-handle = <0x23>;
				status = "disabled";
			};

			mdio@e7000 {
				#address-cells = <0x01>;
				#size-cells = <0x00>;
				compatible = "fsl,fman-memac-mdio\0fsl,fman-xmdio";
				reg = <0xe7000 0x1000>;
				status = "disabled";

				ethernet-phy@0 {
					reg = <0x00>;
					phandle = <0x23>;
				};
			};

			port@8c000 {
				cell-index = <0x0c>;
				compatible = "fsl,fman-v3-port-rx";
				reg = <0x8c000 0x1000>;
				phandle = <0x24>;
			};

			port@ac000 {
				cell-index = <0x2c>;
				compatible = "fsl,fman-v3-port-tx";
				reg = <0xac000 0x1000>;
				phandle = <0x25>;
			};

			ethernet@e8000 {
				cell-index = <0x04>;
				compatible = "fsl,fman-memac";
				reg = <0xe8000 0x1000>;
				fsl,fman-ports = <0x24 0x25>;
				ptp-timer = <0x17>;
				pcsphy-handle = <0x26>;
				status = "disabled";
			};

			mdio@e9000 {
				#address-cells = <0x01>;
				#size-cells = <0x00>;
				compatible = "fsl,fman-memac-mdio\0fsl,fman-xmdio";
				reg = <0xe9000 0x1000>;
				status = "disabled";

				ethernet-phy@0 {
					reg = <0x00>;
					phandle = <0x26>;
				};
			};

			port@8d000 {
				cell-index = <0x0d>;
				compatible = "fsl,fman-v3-port-rx";
				reg = <0x8d000 0x1000>;
				phandle = <0x27>;
			};

			port@ad000 {
				cell-index = <0x2d>;
				compatible = "fsl,fman-v3-port-tx";
				reg = <0xad000 0x1000>;
				phandle = <0x28>;
			};

			ethernet@ea000 {
				cell-index = <0x05>;
				compatible = "fsl,fman-memac";
				reg = <0xea000 0x1000>;
				fsl,fman-ports = <0x27 0x28>;
				ptp-timer = <0x17>;
				pcsphy-handle = <0x29>;
				status = "disabled";
			};

			mdio@eb000 {
				#address-cells = <0x01>;
				#size-cells = <0x00>;
				compatible = "fsl,fman-memac-mdio\0fsl,fman-xmdio";
				reg = <0xeb000 0x1000>;
				status = "disabled";

				ethernet-phy@0 {
					reg = <0x00>;
					phandle = <0x29>;
				};
			};

			port@90000 {
				cell-index = <0x10>;
				compatible = "fsl,fman-v3-port-rx";
				reg = <0x90000 0x1000>;
				fsl,fman-10g-port;
				phandle = <0x2a>;
			};

			port@b0000 {
				cell-index = <0x30>;
				compatible = "fsl,fman-v3-port-tx";
				reg = <0xb0000 0x1000>;
				fsl,fman-10g-port;
				phandle = <0x2b>;
			};

			ethernet@f0000 {
				cell-index = <0x08>;
				compatible = "fsl,fman-memac";
				reg = <0xf0000 0x1000>;
				fsl,fman-ports = <0x2a 0x2b>;
				pcsphy-handle = <0x2c>;
				phy-connection-type = "sgmii";
				local-mac-address = [00 00 00 00 00 00];

				fixed-link {
					speed = <0x3e8>;
					full-duplex;
				};
			};

			mdio@f1000 {
				#address-cells = <0x01>;
				#size-cells = <0x00>;
				compatible = "fsl,fman-memac-mdio\0fsl,fman-xmdio\0adv,mdio-tbi";
				reg = <0xf1000 0x1000>;

				ethernet-phy@0 {
					reg = <0x00>;
					phandle = <0x2c>;
				};
			};
		};

		ptp-timer@1afe000 {
			compatible = "fsl,fman-ptp-timer";
			reg = <0x00 0x1afe000 0x00 0x1000>;
			interrupts = <0x00 0x2c 0x04>;
			clocks = <0x02 0x03 0x00>;
			fsl,extts-fifo;
			status = "disabled";
			phandle = <0x17>;
		};
	};

	firmware {

		optee {
			compatible = "linaro,optee-tz";
			method = "smc";
		};
	};
};
